# MIMXRT1062 register map
Vendor: nxp.com; File version: 1.0
CPU: CM7 r0p1, little endian, MPU, FPU, VTOR, 4 interrupt priority bits
Registers are 32-bit, read-write, reset 0x0 unless marked. A register's access mark holds for its fields unless they carry their own. Offsets are from the block's base; [hi:lo] are bit positions; {n}, {i} and the like mark numbered series; 'fields as' and 'values as' point back to an identical list.

## SRC
Base 0x400F8000; register names take the prefix SRC_
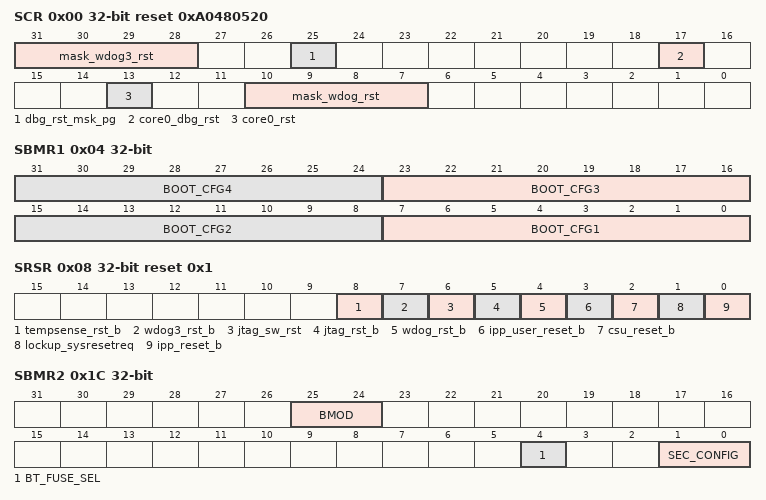
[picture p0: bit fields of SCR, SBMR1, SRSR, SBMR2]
0x00 SCR reset 0xA0480520 — SRC Control Register
  [31:28] mask_wdog3_rst — Mask wdog3_rst_b source
    5=wdog3_rst_b is masked; 10=wdog3_rst_b is not masked
  [25] dbg_rst_msk_pg — Do not assert debug resets after power gating event of core
    0=do not mask core debug resets (debug resets will be asserted after power gating event); 1=mask core debug resets (debug resets won't be asserted after power gating event)
  [17] core0_dbg_rst — Software reset for core0 debug only
    0=do not assert core0 debug reset; 1=assert core0 debug reset
  [13] core0_rst — Software reset for core0 only
    0=do not assert core0 reset; 1=assert core0 reset
  [10:7] mask_wdog_rst — Mask wdog_rst_b source
    5=wdog_rst_b is masked; 10=wdog_rst_b is not masked (default)
0x04 SBMR1 ro — SRC Boot Mode Register 1
  [8n-1:8n-8] BOOT_CFG{n} (n=1..4) — Refer to fusemap.
0x08 SRSR reset 0x1 — SRC Reset Status Register
  [8] tempsense_rst_b — Temper Sensor software reset
    0=Reset is not a result of software reset from Temperature Sensor; 1=Reset is a result of software reset from Temperature Sensor
  [7] wdog3_rst_b write-1-clears — IC Watchdog3 Time-out reset
    0=Reset is not a result of the watchdog3 time-out event; 1=Reset is a result of the watchdog3 time-out event
  [6] jtag_sw_rst write-1-clears — JTAG software reset. Indicates whether the reset was the result of software reset from JTAG.
    0=Reset is not a result of the mentioned case; 1=Reset is a result of the mentioned case
  [5] jtag_rst_b write-1-clears — HIGH - Z JTAG reset. Indicates whether the reset was the result of HIGH-Z reset from JTAG.
    0=Reset is not a result of HIGH-Z reset from JTAG; 1=Reset is a result of HIGH-Z reset from JTAG
  [4] wdog_rst_b write-1-clears — IC Watchdog Time-out reset
    0=Reset is not a result of the watchdog time-out event; 1=Reset is a result of the watchdog time-out event
  [3] ipp_user_reset_b write-1-clears — Indicates whether the reset was the result of the ipp_user_reset_b qualified reset.
    0=Reset is not a result of the ipp_user_reset_b qualified as COLD reset event; 1=Reset is a result of the ipp_user_reset_b qualified as COLD reset event
  [2] csu_reset_b write-1-clears — Indicates whether the reset was the result of the csu_reset_b input.
    0=Reset is not a result of the csu_reset_b event; 1=Reset is a result of the csu_reset_b event
  [1] lockup_sysresetreq write-1-clears — Indicates a reset has been caused by CPU lockup or software setting of SYSRESETREQ bit in Application Interrupt and Reset Control Register of the Arm core
    values as jtag_sw_rst
  [0] ipp_reset_b write-1-clears — Indicates whether reset was the result of ipp_reset_b pin (Power-up sequence)
    0=Reset is not a result of ipp_reset_b pin; 1=Reset is a result of ipp_reset_b pin
0x1C SBMR2 ro — SRC Boot Mode Register 2
  [25:24] BMOD — BMOD[1:0] shows the latched state of the BOOT_MODE1 and BOOT_MODE0 signals on the rising edge of POR_B
  [4] BT_FUSE_SEL — BT_FUSE_SEL (connected to gpio bt_fuse_sel) shows the state of the BT_FUSE_SEL fuse
  [1:0] SEC_CONFIG — SECONFIG[1] shows the state of the SECONFIG[1] fuse
0x20 GPR1 — SRC General Purpose Register 1
  [31:0] PERSISTENT_ENTRY0 — Holds entry function for core0 for waking-up from low power mode
0x24 GPR2 — SRC General Purpose Register 2
  [31:0] PERSISTENT_ARG0 — Holds argument of entry function for core0 for waking-up from low power mode
{0x1C+4i} GPR{i} (i=3..8) — SRC General Purpose Register {i}
0x40 GPR9 ro — SRC General Purpose Register 9
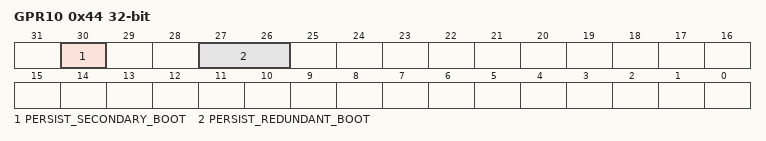
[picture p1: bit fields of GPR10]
0x44 GPR10 — SRC General Purpose Register 10
  [30] PERSIST_SECONDARY_BOOT — This bit identifies which image must be used - primary and secondary
  [27:26] PERSIST_REDUNDANT_BOOT — This field identifies which image must be used - 0/1/2/3
